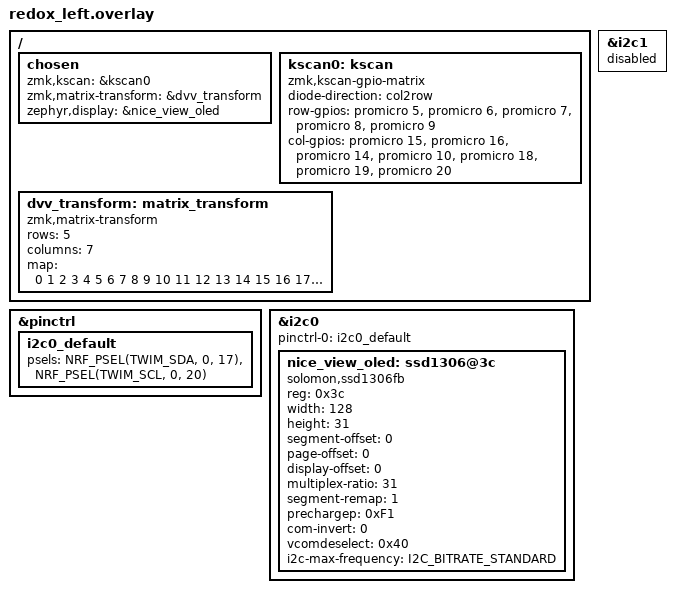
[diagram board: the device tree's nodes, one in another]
#include <dt-bindings/zmk/matrix_transform.h>
&pinctrl {
    i2c0_default: i2c0_default {
        psels = <NRF_PSEL(TWIM_SDA, 0, 17)>,  /* P0.17 */
                <NRF_PSEL(TWIM_SCL, 0, 20)>;  /* P0.20 */
    };
};
&i2c0 {
    status = "okay";
    pinctrl-0 = <&i2c0_default>;
    pinctrl-names = "default";
    nice_view_oled: ssd1306@3c {
        compatible = "solomon,ssd1306fb";
        reg = <0x3c>;
        width = <128>;
        height = <31>;
        segment-offset = <0>;
        page-offset = <0>;
        display-offset = <0>;
        multiplex-ratio = <31>;
        segment-remap = <1>;
        prechargep = <0xF1>;
        com-invert = <0>;
        vcomdeselect = <0x40>;
        i2c-max-frequency = <I2C_BITRATE_STANDARD>;
        // reset-gpios = <&gpio0 10 GPIO_ACTIVE_LOW>; // если используешь RESET
    };
};

&i2c1 {
    status = "disabled";
};
/ {
    chosen {
        zmk,kscan = &kscan0;
        zmk,matrix-transform = &dvv_transform;
        zephyr,display = &nice_view_oled;
    };

    kscan0: kscan {
        compatible = "zmk,kscan-gpio-matrix";
        diode-direction = "col2row";
        
        /* 5 рядов: D5–D9 => P0.24, P1.00, P0.11, P1.04, P1.06 */
        row-gpios = <&promicro 5 (GPIO_ACTIVE_HIGH | GPIO_PULL_DOWN)>,  // D5
                    <&promicro 6 (GPIO_ACTIVE_HIGH | GPIO_PULL_DOWN)>,   // D6
                    <&promicro 7 (GPIO_ACTIVE_HIGH | GPIO_PULL_DOWN)>,  // D7
                    <&promicro 8 (GPIO_ACTIVE_HIGH | GPIO_PULL_DOWN)>,   // D8
                    <&promicro 9 (GPIO_ACTIVE_HIGH | GPIO_PULL_DOWN)>;   // D9

        /* 7 столбцов: D10, D16, D14, D15, D18, D19, D20 */
        col-gpios = <&promicro 15 GPIO_ACTIVE_HIGH>,  // D15 - столбец 1 (TAB)
                    <&promicro 16 GPIO_ACTIVE_HIGH>,  // D16 - столбец 2 (Q)
                    <&promicro 14 GPIO_ACTIVE_HIGH>,  // D14 - столбец 3 (W)
                    <&promicro 10 GPIO_ACTIVE_HIGH>,   // D10 - столбец 4 (E)
                    <&promicro 18 GPIO_ACTIVE_HIGH>,  // D18 - столбец 5 (R)
                    <&promicro 19 GPIO_ACTIVE_HIGH>,   // D19 - столбец 6 (T)
                    <&promicro 20 GPIO_ACTIVE_HIGH>;  // D20 - столбец 7 (пустой)
    };

    dvv_transform: matrix_transform {
        compatible = "zmk,matrix-transform";
        rows = <5>;
        columns = <7>;
        map = <
            0 1 2 3 4 5 6
            7 8 9 10 11 12 13
            14 15 16 17 18 19 20
            21 22 23 24 25 26 27
            28 29 30 31 32 33 34
        >;
    };
};

//&i2c0 {
//    status = "okay";
//    nice_view_oled: ssd1306@3c {
//        compatible = "solomon,ssd1306fb";
//        reg = <0x3c>;
//        width = <128>;
//        height = <64>;
//        segment-offset = <0>;
//        page-offset = <0>;
//        display-offset = <0>;
//        multiplex-ratio = <31>;
//        prechargep = <0x22>;
//       // reset-gpios = <&gpio0 10 GPIO_ACTIVE_LOW>;
//    };
//};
